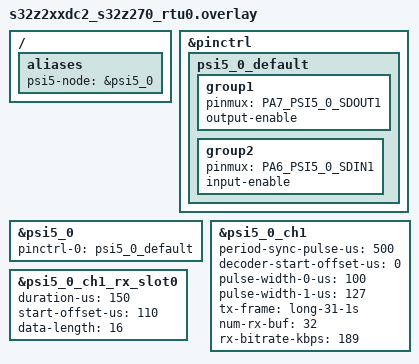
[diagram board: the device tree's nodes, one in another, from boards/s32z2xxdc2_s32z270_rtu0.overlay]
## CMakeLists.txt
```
# SPDX-License-Identifier: Apache-2.0

cmake_minimum_required(VERSION 3.28.0)

find_package(Zephyr REQUIRED HINTS $ENV{ZEPHYR_BASE})
project(psi5)

FILE(GLOB app_sources src/*.c)
target_sources(app PRIVATE ${app_sources})
```

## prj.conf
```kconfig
CONFIG_ZTEST=y
CONFIG_PSI5=y
```

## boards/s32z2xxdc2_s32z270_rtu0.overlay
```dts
/*
 * Copyright 2025 NXP
 *
 * SPDX-License-Identifier: Apache-2.0
 */

/ {
	aliases {
		psi5-node = &psi5_0;
	};
};

&pinctrl {
	psi5_0_default: psi5_0_default {
		group1 {
			pinmux = <PA7_PSI5_0_SDOUT1>;
			output-enable;
		};
		group2 {
			pinmux = <PA6_PSI5_0_SDIN1>;
			input-enable;
		};
	};
};

&psi5_0 {
	pinctrl-0 = <&psi5_0_default>;
	pinctrl-names = "default";
	status = "okay";
};

&psi5_0_ch1 {
	period-sync-pulse-us = <500>;
	decoder-start-offset-us = <0>;
	pulse-width-0-us = <100>;
	pulse-width-1-us = <127>;
	tx-frame = "long-31-1s";
	num-rx-buf = <32>;
	rx-bitrate-kbps = <189>;
	status = "okay";
};

&psi5_0_ch1_rx_slot0 {
	duration-us = <150>;
	start-offset-us = <110>;
	data-length = <16>;
	status = "okay";
};
```

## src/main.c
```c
/*
 * Copyright 2025 NXP
 *
 * SPDX-License-Identifier: Apache-2.0
 */

#include <zephyr/ztest.h>
#include <zephyr/device.h>
#include <zephyr/drivers/psi5/psi5.h>

#define PSI5_NODE          DT_ALIAS(psi5_0)
#define PSI5_CHANNEL       1
#define PSI5_MAX_RX_BUFFER 1

const struct device *psi5_dev = DEVICE_DT_GET(PSI5_NODE);
struct k_sem tx_callback_sem;

struct psi5_frame serial_frame[PSI5_MAX_RX_BUFFER];

struct psi5_frame data_frame[PSI5_MAX_RX_BUFFER];

static void *psi5_setup(void)
{
	int err;

	k_sem_init(&tx_callback_sem, 0, 1);

	zassert_true(device_is_ready(psi5_dev), "PSI5 device is not ready");

	err = psi5_start_sync(psi5_dev, PSI5_CHANNEL);
	zassert_ok(err, "Failed to start sync (err %d)", err);

	return NULL;
}

void rx_serial_frame_cb(const struct device *dev, uint8_t channel_id, uint32_t num_frame,
			void *user_data)
{
	ARG_UNUSED(dev);
	ARG_UNUSED(channel_id);
	ARG_UNUSED(num_frame);
	ARG_UNUSED(user_data);
}

void rx_data_frame_cb(const struct device *dev, uint8_t channel_id, uint32_t num_frame,
		      void *user_data)
{
	ARG_UNUSED(dev);
	ARG_UNUSED(channel_id);
	ARG_UNUSED(num_frame);
	ARG_UNUSED(user_data);
}

void tx_cb(const struct device *dev, uint8_t channel_id, int status, void *user_data)
{
	ARG_UNUSED(dev);
	ARG_UNUSED(channel_id);
	ARG_UNUSED(status);
	ARG_UNUSED(user_data);

	k_sem_give(&tx_callback_sem);
}

/**
 * @brief Test starting sync is not allowed while started.
 */
ZTEST_USER(psi5_api, test_start_sync_while_started)
{
	int err;

	err = psi5_start_sync(psi5_dev, PSI5_CHANNEL);
	zassert_not_ok(err, "Started sync while started");
	zassert_equal(err, -EALREADY, "Wrong error return code (err %d)", err);
}

/**
 * @brief Test stopping sync is not allowed while stopped.
 */
ZTEST_USER(psi5_api, test_stop_sync_while_stopped)
{
	int err;

	err = psi5_stop_sync(psi5_dev, PSI5_CHANNEL);
	zassert_ok(err, "Failed to stop sync (err %d)", err);

	err = psi5_stop_sync(psi5_dev, PSI5_CHANNEL);
	zassert_not_ok(err, "Stopped sync while stopped");
	zassert_equal(err, -EALREADY, "Wrong error return code (err %d)", err);

	err = psi5_start_sync(psi5_dev, PSI5_CHANNEL);
	zassert_ok(err, "Failed to start sync (err %d)", err);
}

struct psi5_rx_callback_config serial_cb_cfg = {
	.callback = rx_serial_frame_cb,
	.frame = &serial_frame[0],
	.max_num_frame = PSI5_MAX_RX_BUFFER,
	.user_data = NULL,
};

struct psi5_rx_callback_config data_cb_cfg = {
	.callback = rx_data_frame_cb,
	.frame = &data_frame[0],
	.max_num_frame = PSI5_MAX_RX_BUFFER,
	.user_data = NULL,
};

struct psi5_rx_callback_configs callback_configs = {
	.serial_frame = &serial_cb_cfg,
	.data_frame = &data_cb_cfg,
};

/**
 * @brief Test setting the rx callback.
 */
ZTEST(psi5_api, test_set_rx_callback)
{
	int err;

	err = psi5_register_callback(psi5_dev, PSI5_CHANNEL, callback_configs);
	zassert_ok(err, "Failed to set rx callback (err %d)", err);

	callback_configs.serial_frame = NULL;
	callback_configs.data_frame = NULL;

	err = psi5_register_callback(psi5_dev, PSI5_CHANNEL, callback_configs);
	zassert_ok(err, "Failed to set rx callback (err %d)", err);

	callback_configs.serial_frame = &serial_cb_cfg;
	callback_configs.data_frame = &data_cb_cfg;

	err = psi5_register_callback(psi5_dev, PSI5_CHANNEL, callback_configs);
	zassert_ok(err, "Failed to set rx callback (err %d)", err);
}

/**
 * @brief Test sending data with callback.
 */
ZTEST(psi5_api, test_send_callback)
{
	int err;
	uint64_t send_data = 0x1234;

	k_sem_reset(&tx_callback_sem);

	err = psi5_send(psi5_dev, PSI5_CHANNEL, send_data, K_MSEC(100), tx_cb, NULL);
	zassert_ok(err, "Failed to send (err %d)", err);

	err = k_sem_take(&tx_callback_sem, K_MSEC(100));
	zassert_ok(err, "missing TX callback");
}

/**
 * @brief Test sending data without callback.
 */
ZTEST(psi5_api, test_send_without_callback)
{
	int err;
	uint64_t send_data = 0x1234;

	err = psi5_send(psi5_dev, PSI5_CHANNEL, send_data, K_MSEC(100), NULL, NULL);
	zassert_ok(err, "Failed to send (err %d)", err);
}

/**
 * @brief Test sending data is not allowed while stopped sync.
 */
ZTEST(psi5_api, test_send_while_stopped_sync)
{
	int err;
	uint64_t send_data = 0x1234;

	err = psi5_stop_sync(psi5_dev, PSI5_CHANNEL);
	zassert_ok(err, "Failed to stop sync (err %d)", err);

	err = psi5_send(psi5_dev, PSI5_CHANNEL, send_data, K_MSEC(100), NULL, NULL);
	zassert_not_ok(err, "Sent data while stopped sync");
	zassert_equal(err, -ENETDOWN, "Wrong error return code (err %d)", err);

	err = psi5_start_sync(psi5_dev, PSI5_CHANNEL);
	zassert_ok(err, "Failed to start sync (err %d)", err);
}

ZTEST_SUITE(psi5_api, NULL, psi5_setup, NULL, NULL, NULL);
```
